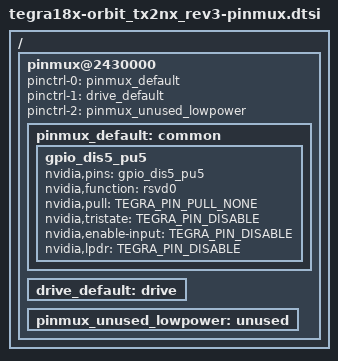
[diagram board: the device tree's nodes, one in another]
/*This dtsi file was generated by orbit_tx2nx.xlsm Revision:  */
/*
 * Copyright (c) 2017, NVIDIA CORPORATION.  All rights reserved.
 *
 * This program is free software; you can redistribute it and/or modify
 * it under the terms of the GNU General Public License as published by
 * the Free Software Foundation; either version 2 of the License, or
 * (at your option) any later version.
 *
 * This program is distributed in the hope that it will be useful, but WITHOUT
 * ANY WARRANTY; without even the implied warranty of MERCHANTABILITY or
 * FITNESS FOR A PARTICULAR PURPOSE.  See the GNU General Public License for
 * more details.
 */

#include <dt-bindings/pinctrl/pinctrl-tegra.h>

/ {
	pinmux@2430000 {
		pinctrl-names = "default", "drive", "unused";
		pinctrl-0 = <&pinmux_default>;
		pinctrl-1 = <&drive_default>;
		pinctrl-2 = <&pinmux_unused_lowpower>;

		pinmux_default: common {
			/* SFIO Pin Configuration */

			gpio_dis5_pu5 {
				nvidia,pins = "gpio_dis5_pu5";
				nvidia,function = "rsvd0";
				nvidia,pull = <TEGRA_PIN_PULL_NONE>;
				nvidia,tristate = <TEGRA_PIN_DISABLE>;
				nvidia,enable-input = <TEGRA_PIN_DISABLE>;
				nvidia,lpdr = <TEGRA_PIN_DISABLE>;
			};

		};
		drive_default: drive {
		};

		pinmux_unused_lowpower: unused {
		};
	};
};
